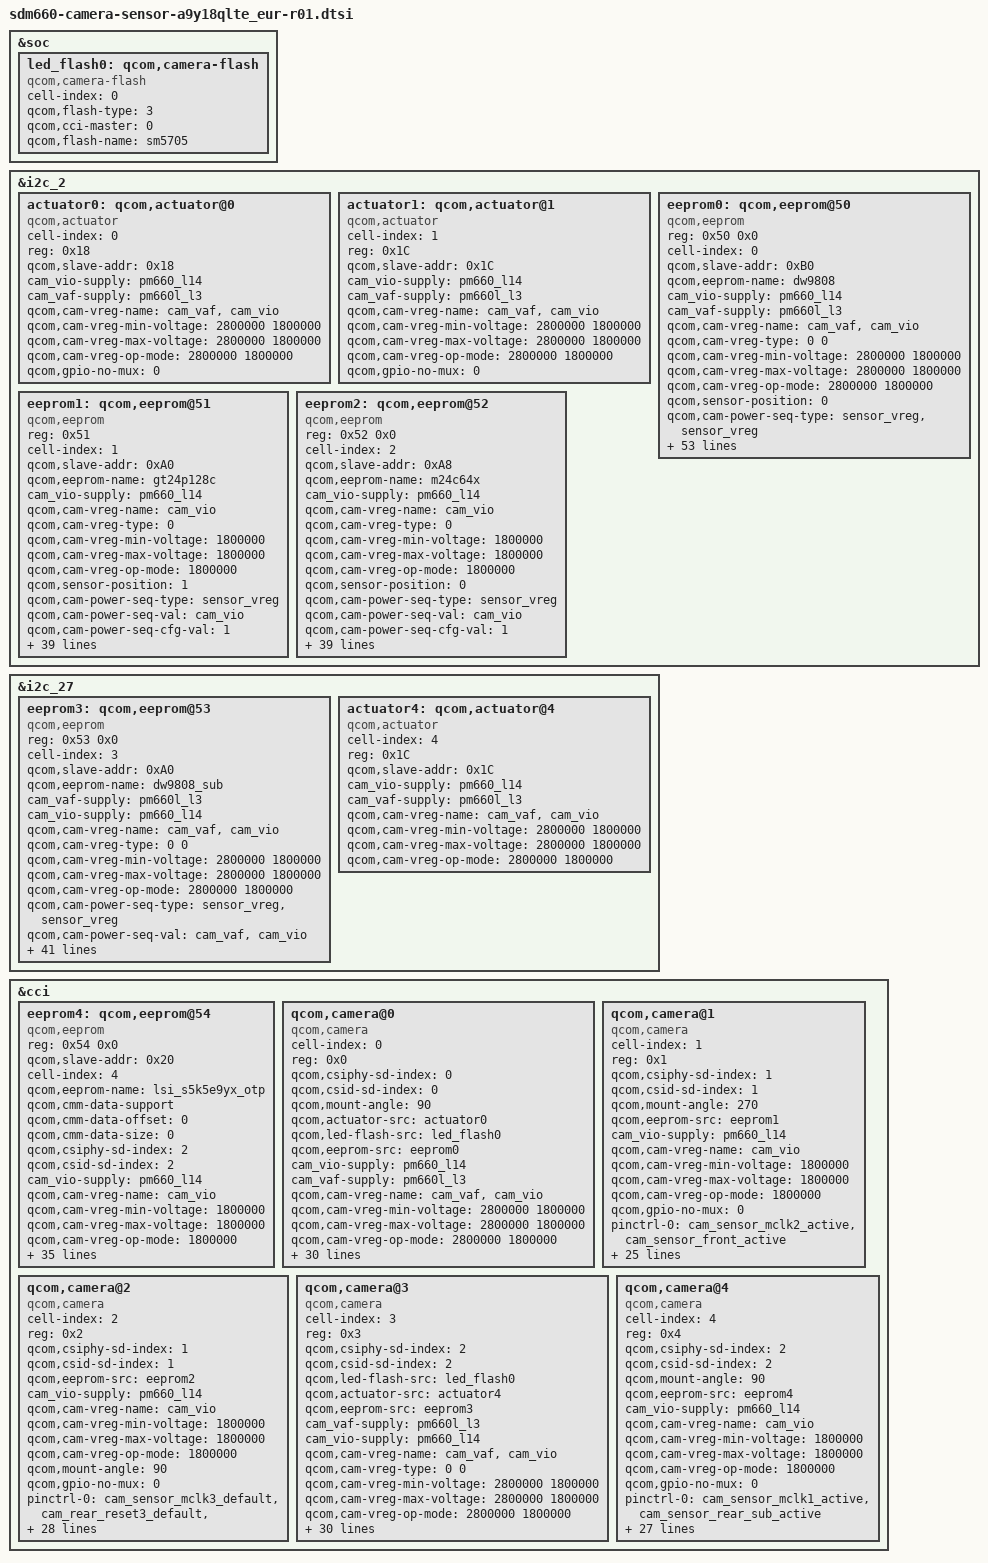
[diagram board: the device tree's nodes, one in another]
/*
 * Copyright (c) 2017, The Linux Foundation. All rights reserved.
 *
 * This program is free software; you can redistribute it and/or modify
 * it under the terms of the GNU General Public License version 2 and
 * only version 2 as published by the Free Software Foundation.
 *
 * This program is distributed in the hope that it will be useful,
 * but WITHOUT ANY WARRANTY; without even the implied warranty of
 * MERCHANTABILITY or FITNESS FOR A PARTICULAR PURPOSE.  See the
 * GNU General Public License for more details.
 */

&soc {
	led_flash0: qcom,camera-flash {
		cell-index = <0>;
		compatible = "qcom,camera-flash";
		qcom,flash-type = <3>;
		qcom,cci-master = <0>;
		qcom,flash-name = "sm5705";
	};
};

&i2c_2 {
	// Rear Main
	actuator0: qcom,actuator@0 {
		compatible = "qcom,actuator";
		cell-index = <0>;
		reg = <0x18>;
		qcom,slave-addr = <0x18>;
		cam_vio-supply = <&pm660_l14>;
		cam_vaf-supply = <&pm660l_l3>;
		qcom,cam-vreg-name = "cam_vaf", "cam_vio";
		qcom,cam-vreg-min-voltage = <2800000 1800000>;
		qcom,cam-vreg-max-voltage = <2800000 1800000>;
		qcom,cam-vreg-op-mode = <2800000 1800000>;
		qcom,gpio-no-mux = <0>;
	};
	// Rear Sub
	actuator1: qcom,actuator@1 {
		compatible = "qcom,actuator";
		cell-index = <1>;
		reg = <0x1C>;
		qcom,slave-addr = <0x1C>;
		cam_vio-supply = <&pm660_l14>;
		cam_vaf-supply = <&pm660l_l3>;
		qcom,cam-vreg-name = "cam_vaf", "cam_vio";
		qcom,cam-vreg-min-voltage = <2800000 1800000>;
		qcom,cam-vreg-max-voltage = <2800000 1800000>;
		qcom,cam-vreg-op-mode = <2800000 1800000>;
		qcom,gpio-no-mux = <0>;
	};
	eeprom0: qcom,eeprom@50 {
		compatible = "qcom,eeprom";
		reg = <0x50 0x0>;
		cell-index = <0>;
		qcom,slave-addr = <0xB0>;
		qcom,eeprom-name = "dw9808";
		cam_vio-supply = <&pm660_l14>;
		cam_vaf-supply = <&pm660l_l3>;
		qcom,cam-vreg-name = "cam_vaf", "cam_vio";
		qcom,cam-vreg-type = <0 0>;
		qcom,cam-vreg-min-voltage = <2800000 1800000>;
		qcom,cam-vreg-max-voltage = <2800000 1800000>;
		qcom,cam-vreg-op-mode = <2800000 1800000>;
		qcom,sensor-position = <0>;
		
		qcom,cam-power-seq-type = "sensor_vreg", "sensor_vreg";
		qcom,cam-power-seq-val = "cam_vaf","cam_vio";
		qcom,cam-power-seq-cfg-val = <1 1>;
		qcom,cam-power-seq-delay = <2 2>;

		qcom,num-blocks = <16>;
		qcom,page0 = <0 0 0 0 0 0>;
		qcom,poll0 = <0 0 0 0 0 0>;
		qcom,mem0 = <0xFC 0x00 2 0 1 0>;

		qcom,page1 = <0 0 0 0 0 0>;
		qcom,poll1 = <0 0 0 0 0 0>;
		qcom,mem1 = <0x4 0xFC 2 0 1 0>;

		qcom,page2 = <0 0 0 0 0 0>;
		qcom,poll2 = <0 0 0 0 0 0>;
		qcom,mem2 = <0x708 0x100 2 0 1 0>;

		qcom,page3 = <0 0 0 0 0 0>;
		qcom,poll3 = <0 0 0 0 0 0>;
		qcom,mem3 = <0x4 0x808 2 0 1 0>;

		qcom,page4 = <0 0 0 0 0 0>;
		qcom,poll4 = <0 0 0 0 0 0>;
		qcom,mem4 = <0x7A 0x80C 2 0 1 0>;

		qcom,page5 = <0 0 0 0 0 0>;
		qcom,poll5 = <0 0 0 0 0 0>;
		qcom,mem5 = <0x4 0x886 2 0 1 0>;

		qcom,page6 = <0 0 0 0 0 0>;
		qcom,poll6 = <0 0 0 0 0 0>;
		qcom,mem6 = <0x26 0x88A 2 0 1 0>;

		qcom,page7 = <0 0 0 0 0 0>;
		qcom,poll7 = <0 0 0 0 0 0>;
		qcom,mem7 = <0x4 0x8B0 2 0 1 0>;

		qcom,page8 = <0 0 0 0 0 0>;
		qcom,poll8 = <0 0 0 0 0 0>;
		qcom,mem8 = <0x2E 0x8B4 2 0 1 0>;

		qcom,page9 = <0 0 0 0 0 0>;
		qcom,poll9 = <0 0 0 0 0 0>;
		qcom,mem9 = <0x4 0x8E2 2 0 1 0>;

		qcom,page10 = <0 0 0 0 0 0>;
		qcom,poll10 = <0 0 0 0 0 0>;
		qcom,mem10 = <0x806 0x8E6 2 0 1 0>;

		qcom,page11 = <0 0 0 0 0 0>;
		qcom,poll11 = <0 0 0 0 0 0>;
		qcom,mem11 = <0x4 0x10EC 2 0 1 0>;

		qcom,page12 = <0 0 0 0 0 0>;
		qcom,poll12 = <0 0 0 0 0 0>;
		qcom,mem12 = <0x6FC 0x1100 2 0 1 0>;

		qcom,page13 = <0 0 0 0 0 0>;
		qcom,poll13 = <0 0 0 0 0 0>;
		qcom,mem13 = <0x4 0x17FC 2 0 1 0>;

		qcom,page14 = <0 0 0 0 0 0>;
		qcom,poll14 = <0 0 0 0 0 0>;
		qcom,mem14 = <0xCFC 0x1800 2 0 1 0>;

		qcom,page15 = <0 0 0 0 0 0>;
		qcom,poll15 = <0 0 0 0 0 0>;
		qcom,mem15 = <0x4 0x24FC 2 0 1 0>;

		qcom,total-size = <0x2500>;
	};
	eeprom1: qcom,eeprom@51 {
		compatible = "qcom,eeprom";
		reg = <0x51>;
		cell-index = <1>;
		qcom,slave-addr = <0xA0>;
		qcom,eeprom-name = "gt24p128c";
		cam_vio-supply = <&pm660_l14>;
		qcom,cam-vreg-name = "cam_vio";
		qcom,cam-vreg-type = <0>;
		qcom,cam-vreg-min-voltage = <1800000>;
		qcom,cam-vreg-max-voltage = <1800000>;
		qcom,cam-vreg-op-mode = <1800000>;
		qcom,sensor-position = <1>;
		qcom,cam-power-seq-type = "sensor_vreg";
		qcom,cam-power-seq-val = "cam_vio";
		qcom,cam-power-seq-cfg-val = <1>;
		qcom,cam-power-seq-delay = <2>;

		qcom,num-blocks = <12>;
		qcom,page0 = <0 0 0 0 0 0>;
		qcom,poll0 = <0 0 0 0 0 0>;
		qcom,mem0 = <0xBE 0x00 2 0 1 0>;

		qcom,page1 = <0 0 0 0 0 0>;
		qcom,poll1 = <0 0 0 0 0 0>;
		qcom,mem1 = <0x4 0xE0 2 0 1 0>;

		qcom,page2 = <0 0 0 0 0 0>;
		qcom,poll2 = <0 0 0 0 0 0>;
		qcom,mem2 = <0x708 0xE4 2 0 1 0>;

		qcom,page3 = <0 0 0 0 0 0>;
		qcom,poll3 = <0 0 0 0 0 0>;
		qcom,mem3 = <0x4 0x7EC 2 0 1 0>;

		qcom,page4 = <0 0 0 0 0 0>;
		qcom,poll4 = <0 0 0 0 0 0>;
		qcom,mem4 = <0x38 0x7F0 2 0 1 0>;

		qcom,page5 = <0 0 0 0 0 0>;
		qcom,poll5 = <0 0 0 0 0 0>;
		qcom,mem5 = <0x4 0x828 2 0 1 0>;

		qcom,page6 = <0 0 0 0 0 0>;
		qcom,poll6 = <0 0 0 0 0 0>;
		qcom,mem6 = <0x26 0x82C 2 0 1 0>;

		qcom,page7 = <0 0 0 0 0 0>;
		qcom,poll7 = <0 0 0 0 0 0>;
		qcom,mem7 = <0x4 0x852 2 0 1 0>;

		qcom,page8 = <0 0 0 0 0 0>;
		qcom,poll8 = <0 0 0 0 0 0>;
		qcom,mem8 = <0x1C 0x856 2 0 1 0>;

		qcom,page9 = <0 0 0 0 0 0>;
		qcom,poll9 = <0 0 0 0 0 0>;
		qcom,mem9 = <0x4 0x872 2 0 1 0>;

		qcom,page10 = <0 0 0 0 0 0>;
		qcom,poll10 = <0 0 0 0 0 0>;
		qcom,mem10 = <0xCFC 0x886 2 0 1 0>;

		qcom,page11 = <0 0 0 0 0 0>;
		qcom,poll11 = <0 0 0 0 0 0>;
		qcom,mem11 = <0x4 0x1082 2 0 1 0>;

		qcom,total-size = <0x1586>;

	};
	eeprom2: qcom,eeprom@52 {
		compatible = "qcom,eeprom";
		reg = <0x52 0x0>;
		cell-index = <2>;
		qcom,slave-addr = <0xA8>;
		qcom,eeprom-name = "m24c64x";
		cam_vio-supply = <&pm660_l14>;
		qcom,cam-vreg-name = "cam_vio";
		qcom,cam-vreg-type = <0>;
		qcom,cam-vreg-min-voltage = <1800000>;
		qcom,cam-vreg-max-voltage = <1800000>;
		qcom,cam-vreg-op-mode = <1800000>;
		qcom,sensor-position = <0>;

		qcom,cam-power-seq-type = "sensor_vreg";
		qcom,cam-power-seq-val = "cam_vio";
		qcom,cam-power-seq-cfg-val = <1>;
		qcom,cam-power-seq-delay = <2>;

		qcom,num-blocks = <12>;   /*8MP*/
		qcom,page0 = <0 0 0 0 0 0>;
		qcom,poll0 = <0 0 0 0 0 0>;
		qcom,mem0 = <0xFC 0x00 2 0 1 0>;

		qcom,page1 = <0 0 0 0 0 0>;
		qcom,poll1 = <0 0 0 0 0 0>;
		qcom,mem1 = <0x4 0xFC 2 0 1 0>;

		qcom,page2 = <0 0 0 0 0 0>;
		qcom,poll2 = <0 0 0 0 0 0>;
		qcom,mem2 = <0x708 0x100 2 0 1 0>;

		qcom,page3 = <0 0 0 0 0 0>;
		qcom,poll3 = <0 0 0 0 0 0>;
		qcom,mem3 = <0x4 0x808 2 0 1 0>;

		qcom,page4 = <0 0 0 0 0 0>;
		qcom,poll4 = <0 0 0 0 0 0>;
		qcom,mem4 = <0x76 0x80C 2 0 1 0>;

		qcom,page5 = <0 0 0 0 0 0>;
		qcom,poll5 = <0 0 0 0 0 0>;
		qcom,mem5 = <0x4 0x882 2 0 1 0>;

		qcom,page6 = <0 0 0 0 0 0>;
		qcom,poll6 = <0 0 0 0 0 0>;
		qcom,mem6 = <0x26 0x886 2 0 1 0>;

		qcom,page7 = <0 0 0 0 0 0>;
		qcom,poll7 = <0 0 0 0 0 0>;
		qcom,mem7 = <0x4 0x8AC 2 0 1 0>;

		qcom,page8 = <0 0 0 0 0 0>;
		qcom,poll8 = <0 0 0 0 0 0>;
		qcom,mem8 = <0x3C 0x8B0 2 0 1 0>;

		qcom,page9 = <0 0 0 0 0 0>;
		qcom,poll9 = <0 0 0 0 0 0>;
		qcom,mem9 = <0x4 0x8EC 2 0 1 0>;

		qcom,page10 = <0 0 0 0 0 0>;
		qcom,poll10 = <0 0 0 0 0 0>;
		qcom,mem10 = <0x10 0x8F0 2 0 1 0>;

		qcom,page11 = <0 0 0 0 0 0>;
		qcom,poll11 = <0 0 0 0 0 0>;
		qcom,mem11 = <0x4 0x900 2 0 1 0>;
/*
		qcom,page12 = <0 0 0 0 0 0>;
		qcom,poll12 = <0 0 0 0 0 0>;
		qcom,mem12 = <0x6A 0x100C 2 0 1 0>;

		qcom,page13 = <0 0 0 0 0 0>;
		qcom,poll13 = <0 0 0 0 0 0>;
		qcom,mem13 = <0x4 0x1076 2 0 1 0>;

		qcom,page14 = <0 0 0 0 0 0>;
		qcom,poll14 = <0 0 0 0 0 0>;
		qcom,mem14 = <0x26 0x107A 2 0 1 0>;

		qcom,page15 = <0 0 0 0 0 0>;
		qcom,poll15 = <0 0 0 0 0 0>;
		qcom,mem15 = <0x4 0x10A0 2 0 1 0>;

		qcom,page16 = <0 0 0 0 0 0>;
		qcom,poll16 = <0 0 0 0 0 0>;
		qcom,mem16 = <0x3C 0x10A4 2 0 1 0>;

		qcom,page17 = <0 0 0 0 0 0>;
		qcom,poll17 = <0 0 0 0 0 0>;
		qcom,mem17 = <0x4 0x10E0 2 0 1 0>;

		qcom,page18 = <0 0 0 0 0 0>;
		qcom,poll18 = <0 0 0 0 0 0>;
		qcom,mem18 = <0x808 0x10E4 2 0 1 0>;

		qcom,page19 = <0 0 0 0 0 0>;
		qcom,poll19 = <0 0 0 0 0 0>;
		qcom,mem19 = <0x4 0x18EC 2 0 1 0>;

		qcom,page20 = <0 0 0 0 0 0>;
		qcom,poll20 = <0 0 0 0 0 0>;
		qcom,mem20 = <0x6FC 0x1900 2 0 1 0>;

		qcom,page21 = <0 0 0 0 0 0>;
		qcom,poll21 = <0 0 0 0 0 0>;
		qcom,mem21 = <0x4 0x1FFC 2 0 1 0>;

		qcom,page22 = <0 0 0 0 0 0>;
		qcom,poll22 = <0 0 0 0 0 0>;
		qcom,mem22 = <0xCFC 0x2000 2 0 1 0>;

		qcom,page23 = <0 0 0 0 0 0>;
		qcom,poll23 = <0 0 0 0 0 0>;
		qcom,mem23 = <0x4 0x2CFC 2 0 1 0>;
*/
		qcom,total-size = <0x904>;
	};
};

&i2c_27 {
	eeprom3: qcom,eeprom@53 {
		// 10M Tele sensor eeprom
		compatible = "qcom,eeprom";
		reg = <0x53 0x0>;
		cell-index = <3>;
		qcom,slave-addr = <0xA0>;
		qcom,eeprom-name = "dw9808_sub";
	
		// Regulator configurations
		cam_vaf-supply = <&pm660l_l3>;
		cam_vio-supply = <&pm660_l14>;
		qcom,cam-vreg-name = "cam_vaf", "cam_vio";
		qcom,cam-vreg-type = <0 0>;
		qcom,cam-vreg-min-voltage = <2800000 1800000>;
		qcom,cam-vreg-max-voltage = <2800000 1800000>;
		qcom,cam-vreg-op-mode = <2800000 1800000>;

		// Power-up sequence
		qcom,cam-power-seq-type = "sensor_vreg", "sensor_vreg";
		qcom,cam-power-seq-val = "cam_vaf","cam_vio";
		qcom,cam-power-seq-cfg-val = <1 1>;
		qcom,cam-power-seq-delay = <2 2>;

		// Read configurations
		qcom,num-blocks = <12>;
		qcom,page0 = <0 0 0 0 0 0>;
		qcom,poll0 = <0 0 0 0 0 0>;
		qcom,mem0 = <0xFC 0x00 2 0 1 0>;

		qcom,page1 = <0 0 0 0 0 0>;
		qcom,poll1 = <0 0 0 0 0 0>;
		qcom,mem1 = <0x4 0xFC 2 0 1 0>;

		qcom,page2 = <0 0 0 0 0 0>;
		qcom,poll2 = <0 0 0 0 0 0>;
		qcom,mem2 = <0x708 0x100 2 0 1 0>;

		qcom,page3 = <0 0 0 0 0 0>;
		qcom,poll3 = <0 0 0 0 0 0>;
		qcom,mem3 = <0x4 0x808 2 0 1 0>;

		qcom,page4 = <0 0 0 0 0 0>;
		qcom,poll4 = <0 0 0 0 0 0>;
		qcom,mem4 = <0x76 0x80C 2 0 1 0>;

		qcom,page5 = <0 0 0 0 0 0>;
		qcom,poll5 = <0 0 0 0 0 0>;
		qcom,mem5 = <0x4 0x882 2 0 1 0>;

		qcom,page6 = <0 0 0 0 0 0>;
		qcom,poll6 = <0 0 0 0 0 0>;
		qcom,mem6 = <0x26 0x886 2 0 1 0>;

		qcom,page7 = <0 0 0 0 0 0>;
		qcom,poll7 = <0 0 0 0 0 0>;
		qcom,mem7 = <0x4 0x8AC 2 0 1 0>;

		qcom,page8 = <0 0 0 0 0 0>;
		qcom,poll8 = <0 0 0 0 0 0>;
		qcom,mem8 = <0x3C 0x8B0 2 0 1 0>;

		qcom,page9 = <0 0 0 0 0 0>;
		qcom,poll9 = <0 0 0 0 0 0>;
		qcom,mem9 = <0x4 0x8EC 2 0 1 0>;

		qcom,page10 = <0 0 0 0 0 0>;
		qcom,poll10 = <0 0 0 0 0 0>;
		qcom,mem10 = <0x70C 0x8F0 2 0 1 0>;

		qcom,page11 = <0 0 0 0 0 0>;
		qcom,poll11 = <0 0 0 0 0 0>;
		qcom,mem11 = <0x4 0xFFC 2 0 1 0>;

		qcom,total-size = <0x1000>;

		// Sensor position
		qcom,sensor-position = <0>;
	};

	// Rear Tele
	actuator4: qcom,actuator@4 {
		// 10M sensor actuator
		compatible = "qcom,actuator";
		cell-index = <4>;
		reg = <0x1C>;
		qcom,slave-addr = <0x1C>;

		// Regulator configurations
		cam_vio-supply = <&pm660_l14>;
		cam_vaf-supply = <&pm660l_l3>;
		qcom,cam-vreg-name = "cam_vaf", "cam_vio";
		qcom,cam-vreg-min-voltage = <2800000 1800000>;
		qcom,cam-vreg-max-voltage = <2800000 1800000>;
		qcom,cam-vreg-op-mode = <2800000 1800000>;
	};
};

&cci {
	eeprom4: qcom,eeprom@54 {
		// 5M Camera Sensor OTP
		compatible = "qcom,eeprom";
		reg = <0x54 0x0>;
		qcom,slave-addr = <0x20>;
		cell-index = <4>;
		qcom,eeprom-name = "lsi_s5k5e9yx_otp";
		qcom,cmm-data-support;
		qcom,cmm-data-offset = <0>;
		qcom,cmm-data-size = <0>;
		qcom,csiphy-sd-index = <2>;
		qcom,csid-sd-index = <2>;
		cam_vio-supply = <&pm660_l14>;
		qcom,cam-vreg-name = "cam_vio";
		qcom,cam-vreg-min-voltage = <1800000>;
		qcom,cam-vreg-max-voltage = <1800000>;
		qcom,cam-vreg-op-mode = <1800000>;
		qcom,gpio-no-mux = <0>;
		pinctrl-names = "cam_default", "cam_suspend";
		pinctrl-0 = <&cam_sensor_mclk1_active &cam_sensor_rear_sub_active>;
		pinctrl-1 = <&cam_sensor_mclk1_suspend &cam_sensor_rear_sub_suspend>;
		gpios = <&tlmm 33 0>,
			<&tlmm 48 0>,
			<&expander_gpios 4 0>,
			<&expander_gpios 3 0>;
		qcom,gpio-reset = <1>;
		qcom,gpio-vana = <2>;
		qcom,gpio-custom1 = <3>;
		qcom,gpio-req-tbl-num = <0 1 2 3>;
		qcom,gpio-req-tbl-flags = <1 0 0 0>;
		qcom,gpio-req-tbl-label = "CAMIF_MCLK2",
			"CAM_RESET2",
			"CAM_VANA2",
			"CAM_CUSTOM2";
		qcom,cam-power-seq-type = "sensor_clk",
			"sensor_vreg",
			"sensor_gpio",
			"sensor_gpio";
		qcom,cam-power-seq-val = "sensor_cam_mclk",
			"cam_vio",
			"sensor_gpio_vana",
			"sensor_gpio_reset";
		qcom,cam-power-seq-cfg-val = <24000000 1800000 1 1>;
		qcom,cam-power-seq-delay = <1 1 1 2>;
		qcom,sensor-position = <0>;
		qcom,sensor-mode = <0>;
		qcom,cci-master = <1>;
		status = "ok";
		clocks = <&clock_mmss MCLK1_CLK_SRC>,
			<&clock_mmss MMSS_CAMSS_MCLK1_CLK>;
		clock-names = "cam_src_clk", "cam_clk";
		qcom,clock-rates = <24000000 0>;
		qcom,num-blocks = <2>;
		qcom,page0 = <0 0 0 0 0 0>;
		qcom,poll0 = <0 0 0 0 0 0>;
		qcom,mem0 = <0x00F0 0x000F 2 0 1 0>;
		qcom,page1 = <0 0 0 0 0 0>;
		qcom,poll1 = <0 0 0 0 0 0>;
		qcom,mem1 = <0x0004 0x00FF 2 0 1 0>;
		qcom,total-size = <0x0200>;
	};
	qcom,camera@0 {
		// Rear Main Camera (24M Wide)
		cell-index = <0>;
		compatible = "qcom,camera";
		reg = <0x0>;
		qcom,csiphy-sd-index = <0>;
		qcom,csid-sd-index = <0>;
		qcom,mount-angle = <90>;
		qcom,actuator-src = <&actuator0>;
		qcom,led-flash-src = <&led_flash0>;
		qcom,eeprom-src = <&eeprom0>;
		cam_vio-supply = <&pm660_l14>;
		cam_vaf-supply = <&pm660l_l3>;
		qcom,cam-vreg-name = "cam_vaf", "cam_vio";
		qcom,cam-vreg-min-voltage = <2800000 1800000>;
		qcom,cam-vreg-max-voltage = <2800000 1800000>;
		qcom,cam-vreg-op-mode = <2800000 1800000>;
		qcom,gpio-no-mux = <0>;		
		pinctrl-names = "cam_default", "cam_suspend";
		pinctrl-0 = <&cam_sensor_mclk0_active &cam_sensor_rear_active>;
		pinctrl-1 = <&cam_sensor_mclk0_suspend &cam_sensor_rear_suspend>;
		gpios = <&tlmm 32 0>,
			<&tlmm 46 0>,
			<&expander_gpios 16 0>,
			<&expander_gpios 18 0>;
		qcom,gpio-reset = <1>;
		qcom,gpio-vana = <2>;
		qcom,gpio-vdig = <3>;
		qcom,gpio-req-tbl-num = <0 1 2 3>;
		qcom,gpio-req-tbl-flags = <1 0 0 0>;
		qcom,gpio-req-tbl-label = "CAMIF_MCLK0", "CAM_RESET0", "CAM_VANA", "CAM_VDIG";
		qcom,sensor-position = <0>;
		qcom,sensor-mode = <0>;
		qcom,cci-master = <0>;
		status = "ok";
		clocks = <&clock_mmss MCLK0_CLK_SRC>,
			<&clock_mmss MMSS_CAMSS_MCLK0_CLK>;
		clock-names = "cam_src_clk", "cam_clk";
		qcom,clock-rates = <24000000 0>;
		cam,isp = <0>;                  // 0 : INT , 1 : EXT , 2 : SOC
		cam,cal_memory = <2>;           // 0 : N , 1 : FROM , 2 : EEPROM , 3 : OTP
		cam,read_version = <0>;         // 0 : SYSFS , 1 : CAMON
		cam,core_voltage = <0>;         // 0 : N , 1 : Y
		cam,upgrade = <0>;              // 0 : N , 1 : SYSFS , 2 : CAMON
		cam,fw_write = <0>;             // 0 : N , 1 : OS , 2 : SD , 3 : ALL
		cam,fw_dump = <0>;              // 0 : N , 1 : Y
		cam,companion_chip = <0>;       // 0 : N , 1 : Y
		cam,ois = <0>;                  // 0 : N , 1 : Y
		cam,valid = <1>;                // 0 : N , 1 : Y
	};
	qcom,camera@1 {
		// Front Camera (24M) 
		cell-index = <1>;
		compatible = "qcom,camera";
		reg = <0x1>;
		qcom,csiphy-sd-index = <1>;
		qcom,csid-sd-index = <1>;
		qcom,mount-angle = <270>;
		qcom,eeprom-src = <&eeprom1>;
		cam_vio-supply = <&pm660_l14>;
		qcom,cam-vreg-name = "cam_vio";
		qcom,cam-vreg-min-voltage = <1800000>;
		qcom,cam-vreg-max-voltage = <1800000>;
		qcom,cam-vreg-op-mode = <1800000>;
		qcom,gpio-no-mux = <0>;
		pinctrl-names = "cam_default", "cam_suspend";
		pinctrl-0 = <&cam_sensor_mclk2_active &cam_sensor_front_active>; // &cam_switch_default>;
		pinctrl-1 = <&cam_sensor_mclk2_suspend &cam_sensor_front_suspend>; // &cam_switch_sleep>;
		gpios = <&tlmm 34 0>,
			<&tlmm 47 0>,
			//<&tlmm 86 0>,
			<&expander_gpios 8 0>;
		qcom,gpio-reset = <1>;
		qcom,gpio-vana = <2>;
		//qcom,gpio-custom1 = <3>;
		qcom,gpio-req-tbl-num = <0 1 2>;// 3>;
		qcom,gpio-req-tbl-flags = <1 0 0>;// 0>;
		qcom,gpio-req-tbl-label = "CAMIF_MCLK1","CAM_RESET1", "CAM_VANA"; // "CAM_CUSTOM1";
		qcom,sensor-position = <1>;
		qcom,sensor-mode = <0>;
		qcom,cci-master = <1>;
		status = "ok";
		clocks = <&clock_mmss MCLK2_CLK_SRC>,
			<&clock_mmss MMSS_CAMSS_MCLK2_CLK>;
		clock-names = "cam_src_clk", "cam_clk";
		qcom,clock-rates = <24000000 0>;
		cam,isp = <0>;                  // 0 : INT , 1 : EXT , 2 : SOC
		cam,cal_memory = <2>;           // 0 : N , 1 : FROM , 2 : EEPROM , 3 : OTP
		cam,read_version = <0>;         // 0 : SYSFS , 1 : CAMON
		cam,core_voltage = <0>;         // 0 : N , 1 : Y
		cam,upgrade = <0>;              // 0 : N , 1 : SYSFS , 2 : CAMON
		cam,fw_write = <0>;             // 0 : N , 1 : OS , 2 : SD , 3 : ALL
		cam,fw_dump = <0>;              // 0 : N , 1 : Y
		cam,companion_chip = <0>;       // 0 : N , 1 : Y
		cam,ois = <0>;                  // 0 : N , 1 : Y
		cam,valid = <1>;                // 0 : N , 1 : Y
	};
	qcom,camera@2 {
		// Rear Cam 2 (8M Ultra wide)
		cell-index = <2>;
		compatible = "qcom,camera";
		/*qcom,led-flash-src = <&led_flash1>;*/
		reg = <0x2>;
		qcom,csiphy-sd-index = <1>;
		qcom,csid-sd-index = <1>;
		qcom,eeprom-src = <&eeprom2>;
		cam_vio-supply = <&pm660_l14>;
		qcom,cam-vreg-name = "cam_vio";
		qcom,cam-vreg-min-voltage = <1800000>;
		qcom,cam-vreg-max-voltage = <1800000>;
		qcom,cam-vreg-op-mode = <1800000>;
		qcom,mount-angle = <90>;
		qcom,gpio-no-mux = <0>;
		pinctrl-names = "cam_default", "cam_suspend";
		pinctrl-0 = <&cam_sensor_mclk3_default &cam_rear_reset3_default &cam_rear_vio3_default &cam_switch_default>;
		pinctrl-1 = <&cam_sensor_mclk3_sleep &cam_rear_reset3_sleep &cam_rear_vio3_sleep &cam_switch_default>;
		gpios = <&tlmm 35 0>,
			<&tlmm 96 0>,
			<&tlmm 12 0>,
			<&tlmm 86 0>;
		qcom,gpio-reset = <1>;
		qcom,gpio-vana = <2>;
		qcom,gpio-custom1 = <3>;
		qcom,gpio-req-tbl-num = <0 1 2 3>;
		qcom,gpio-req-tbl-flags = <1 0 0 0>;
		qcom,gpio-req-tbl-label = "CAMIF_MCLK3", "CAM_RESET3", "CAM_VANA", "CAM_CUSTOM1";
		qcom,sensor-position = <0>;
		qcom,sensor-mode = <0>;
		qcom,cci-master = <0>;
		status = "ok";
		clocks = <&clock_mmss MCLK3_CLK_SRC>,
			<&clock_mmss MMSS_CAMSS_MCLK3_CLK>;
		clock-names = "cam_src_clk", "cam_clk";
		qcom,clock-rates = <24000000 0>;
		cam,isp = <0>;                  // 0 : INT , 1 : EXT , 2 : SOC
		cam,cal_memory = <2>;           // 0 : N , 1 : FROM , 2 : EEPROM , 3 : OTP
		cam,read_version = <0>;         // 0 : SYSFS , 1 : CAMON
		cam,core_voltage = <0>;         // 0 : N , 1 : Y
		cam,upgrade = <0>;              // 0 : N , 1 : SYSFS , 2 : CAMON
		cam,fw_write = <0>;             // 0 : N , 1 : OS , 2 : SD , 3 : ALL
		cam,fw_dump = <0>;              // 0 : N , 1 : Y
		cam,companion_chip = <0>;       // 0 : N , 1 : Y
		cam,ois = <0>;                  // 0 : N , 1 : Y
		cam,valid = <1>;
	};
	qcom,camera@3 {
		// Rear Cam 3 (10M Tele)
		cell-index = <3>;
		compatible = "qcom,camera";
		reg = <0x3>;

		// Sub-module configurations
		qcom,csiphy-sd-index = <2>;
		qcom,csid-sd-index = <2>;
                qcom,led-flash-src = <&led_flash0>;
		qcom,actuator-src = <&actuator4>;
		qcom,eeprom-src = <&eeprom3>;

		// Regulator configurations
		cam_vaf-supply = <&pm660l_l3>;
		cam_vio-supply = <&pm660_l14>;
		qcom,cam-vreg-name = "cam_vaf", "cam_vio";
		qcom,cam-vreg-type = <0 0>;
		qcom,cam-vreg-min-voltage = <2800000 1800000>;
		qcom,cam-vreg-max-voltage = <2800000 1800000>;
		qcom,cam-vreg-op-mode = <2800000 1800000>;

		// GPIO configurations
		pinctrl-names = "cam_default", "cam_suspend";
		pinctrl-0 = <&cam_sensor_mclk3_default>;
		pinctrl-1 = <&cam_sensor_mclk3_sleep>;
		gpios = <&tlmm 35 0>,
			<&expander_gpios 2 0>,
			<&expander_gpios 3 0>,
			<&expander_gpios 1 0>;
		qcom,gpio-reset = <1>;
		qcom,gpio-custom1 = <2>;
		qcom,gpio-vana = <3>;
		qcom,gpio-req-tbl-num = <0 1 2 3>;
		qcom,gpio-req-tbl-flags = <1 0 0 0>;
		qcom,gpio-req-tbl-label = "CAMIF_MCLK4",
			"CAM_RESET4",
			"CAM_CUSTOM4",
			"CAM_VANA4";

		// Custom mode
		qcom,secure = <0>;

		// CCI Master
		qcom,cci-master = <1>;

		// Mount angle
		qcom,mount-angle = <90>;
		qcom,sensor-position = <0>;
		qcom,sensor-mode = <0>;

		// Clock configuration
		clocks = <&clock_mmss MCLK3_CLK_SRC>,
			<&clock_mmss MMSS_CAMSS_MCLK3_CLK>;
		clock-names = "cam_src_clk", "cam_clk";
		qcom,clock-rates = <24000000 0>;

		// Camera information
		cam,isp = <0>;                  // 0 : INT , 1 : EXT , 2 : SOC
		cam,cal_memory = <2>;           // 0 : N , 1 : FROM , 2 : EEPROM , 3 : OTP
		cam,read_version = <0>;         // 0 : SYSFS , 1 : CAMON
		cam,core_voltage = <0>;         // 0 : N , 1 : Y
		cam,upgrade = <0>;              // 0 : N , 1 : SYSFS , 2 : CAMON
		cam,fw_write = <0>;             // 0 : N , 1 : OS , 2 : SD , 3 : ALL
		cam,fw_dump = <0>;              // 0 : N , 1 : Y
		cam,companion_chip = <0>;       // 0 : N , 1 : Y
		cam,ois = <0>;                  // 0 : N , 1 : Y
		cam,valid = <1>;                // 0 : N , 1 : Y
		cam,dual_open = <0>;            // 0 : N , 1 : Y
	};
	qcom,camera@4 {
		// Rear Cam 4 (5M Bokeh)
		cell-index = <4>;
		compatible = "qcom,camera";
		reg = <0x4>;
		qcom,csiphy-sd-index = <2>;
		qcom,csid-sd-index = <2>;
		qcom,mount-angle = <90>;
		/* qcom,actuator-src = <&actuator1>;
		qcom,led-flash-src = <&led_flash0>; */
		qcom,eeprom-src = <&eeprom4>;
		cam_vio-supply = <&pm660_l14>;
		qcom,cam-vreg-name = "cam_vio";
		qcom,cam-vreg-min-voltage = <1800000>;
		qcom,cam-vreg-max-voltage = <1800000>;
		qcom,cam-vreg-op-mode = <1800000>;
		qcom,gpio-no-mux = <0>;		
		pinctrl-names = "cam_default", "cam_suspend";
		pinctrl-0 = <&cam_sensor_mclk1_active &cam_sensor_rear_sub_active>;
		pinctrl-1 = <&cam_sensor_mclk1_suspend &cam_sensor_rear_sub_suspend>;
		gpios = <&tlmm 33 0>,
			<&tlmm 48 0>,
			<&expander_gpios 4 0>,
                        <&expander_gpios 3 0>;
		qcom,gpio-reset = <1>;
		qcom,gpio-vana = <2>;
		qcom,gpio-req-tbl-num = <0 1 2>;
		qcom,gpio-req-tbl-flags = <1 0 0>;
		qcom,gpio-req-tbl-label = "CAMIF_MCLK2", "CAM_RESET2", "CAM_VANA";
		qcom,sensor-position = <0>;
		qcom,sensor-mode = <0>;
		qcom,cci-master = <1>;
		status = "ok";
		clocks = <&clock_mmss MCLK1_CLK_SRC>,
			<&clock_mmss MMSS_CAMSS_MCLK1_CLK>;
		clock-names = "cam_src_clk", "cam_clk";
		qcom,clock-rates = <24000000 0>;
	        cam,isp = <0>;                  // 0 : INT , 1 : EXT , 2 : SOC
		cam,cal_memory = <2>;           // 0 : N , 1 : FROM , 2 : EEPROM , 3 : OTP
		cam,read_version = <0>;         // 0 : SYSFS , 1 : CAMON
		cam,core_voltage = <0>;         // 0 : N , 1 : Y
		cam,upgrade = <0>;              // 0 : N , 1 : SYSFS , 2 : CAMON
		cam,fw_write = <0>;             // 0 : N , 1 : OS , 2 : SD , 3 : ALL
		cam,fw_dump = <0>;              // 0 : N , 1 : Y
		cam,companion_chip = <0>;       // 0 : N , 1 : Y
		cam,ois = <0>;                  // 0 : N , 1 : Y
		cam,valid = <1>;                // 0 : N , 1 : Y
		cam,dual_open = <0>;            // 0 : N , 1 : Y
	};

};

